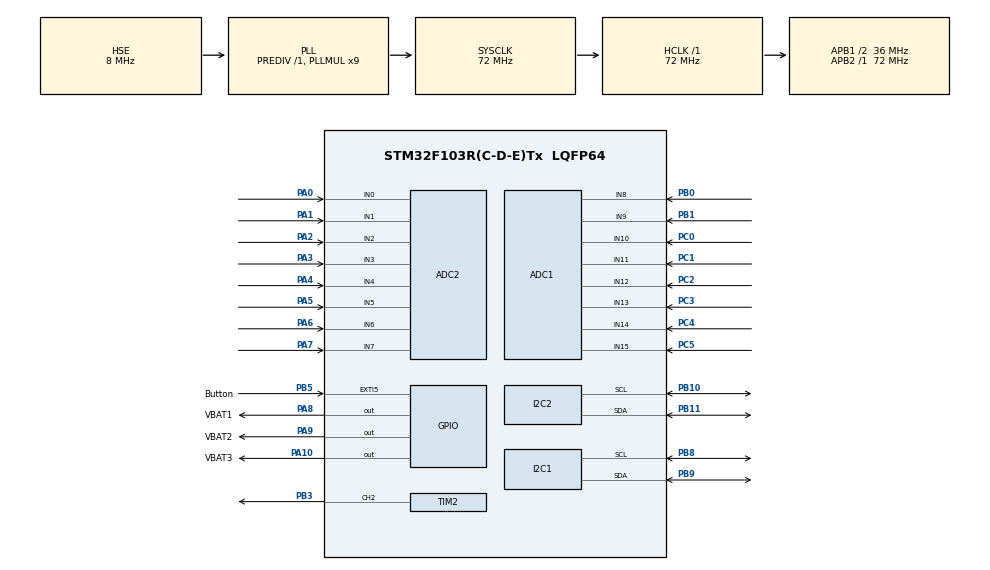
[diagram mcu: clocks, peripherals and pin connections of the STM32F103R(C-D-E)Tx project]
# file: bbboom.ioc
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ADC1.Channel-0\#ChannelRegularConversion=ADC_CHANNEL_8
ADC1.Channel-1\#ChannelRegularConversion=ADC_CHANNEL_9
ADC1.Channel-2\#ChannelRegularConversion=ADC_CHANNEL_10
ADC1.Channel-3\#ChannelRegularConversion=ADC_CHANNEL_11
ADC1.Channel-4\#ChannelRegularConversion=ADC_CHANNEL_12
ADC1.Channel-5\#ChannelRegularConversion=ADC_CHANNEL_13
ADC1.Channel-6\#ChannelRegularConversion=ADC_CHANNEL_14
ADC1.Channel-7\#ChannelRegularConversion=ADC_CHANNEL_15
ADC1.ContinuousConvMode=DISABLE
ADC1.DiscontinuousConvMode=ENABLE
ADC1.NbrOfConversion=8
ADC1.NbrOfConversionFlag=1
ADC1.Rank-0\#ChannelRegularConversion=1
ADC1.Rank-1\#ChannelRegularConversion=2
ADC1.Rank-2\#ChannelRegularConversion=3
ADC1.Rank-3\#ChannelRegularConversion=4
ADC1.Rank-4\#ChannelRegularConversion=5
ADC1.Rank-5\#ChannelRegularConversion=6
ADC1.Rank-6\#ChannelRegularConversion=7
ADC1.Rank-7\#ChannelRegularConversion=8
ADC1.SamplingTime-0\#ChannelRegularConversion=ADC_SAMPLETIME_28CYCLES_5
ADC1.SamplingTime-1\#ChannelRegularConversion=ADC_SAMPLETIME_28CYCLES_5
ADC1.SamplingTime-2\#ChannelRegularConversion=ADC_SAMPLETIME_41CYCLES_5
ADC1.SamplingTime-3\#ChannelRegularConversion=ADC_SAMPLETIME_28CYCLES_5
ADC1.SamplingTime-4\#ChannelRegularConversion=ADC_SAMPLETIME_28CYCLES_5
ADC1.SamplingTime-5\#ChannelRegularConversion=ADC_SAMPLETIME_28CYCLES_5
ADC1.SamplingTime-6\#ChannelRegularConversion=ADC_SAMPLETIME_28CYCLES_5
ADC1.SamplingTime-7\#ChannelRegularConversion=ADC_SAMPLETIME_28CYCLES_5
ADC1.master=1
ADC2.Channel-0\#ChannelRegularConversion=ADC_CHANNEL_0
ADC2.Channel-1\#ChannelRegularConversion=ADC_CHANNEL_1
ADC2.Channel-2\#ChannelRegularConversion=ADC_CHANNEL_2
ADC2.Channel-3\#ChannelRegularConversion=ADC_CHANNEL_3
ADC2.Channel-4\#ChannelRegularConversion=ADC_CHANNEL_4
ADC2.Channel-5\#ChannelRegularConversion=ADC_CHANNEL_5
ADC2.Channel-6\#ChannelRegularConversion=ADC_CHANNEL_6
ADC2.Channel-7\#ChannelRegularConversion=ADC_CHANNEL_7
ADC2.ContinuousConvMode=DISABLE
ADC2.DiscontinuousConvMode=ENABLE
ADC2.NbrOfConversion=8
ADC2.NbrOfConversionFlag=1
ADC2.Rank-0\#ChannelRegularConversion=1
ADC2.Rank-1\#ChannelRegularConversion=2
ADC2.Rank-2\#ChannelRegularConversion=3
ADC2.Rank-3\#ChannelRegularConversion=4
ADC2.Rank-4\#ChannelRegularConversion=5
ADC2.Rank-5\#ChannelRegularConversion=6
ADC2.Rank-6\#ChannelRegularConversion=7
ADC2.Rank-7\#ChannelRegularConversion=8
ADC2.SamplingTime-0\#ChannelRegularConversion=ADC_SAMPLETIME_28CYCLES_5
ADC2.SamplingTime-1\#ChannelRegularConversion=ADC_SAMPLETIME_28CYCLES_5
ADC2.SamplingTime-2\#ChannelRegularConversion=ADC_SAMPLETIME_28CYCLES_5
ADC2.SamplingTime-3\#ChannelRegularConversion=ADC_SAMPLETIME_28CYCLES_5
ADC2.SamplingTime-4\#ChannelRegularConversion=ADC_SAMPLETIME_28CYCLES_5
ADC2.SamplingTime-5\#ChannelRegularConversion=ADC_SAMPLETIME_28CYCLES_5
ADC2.SamplingTime-6\#ChannelRegularConversion=ADC_SAMPLETIME_28CYCLES_5
ADC2.SamplingTime-7\#ChannelRegularConversion=ADC_SAMPLETIME_28CYCLES_5
Mcu.Family=STM32F1
Mcu.Name=STM32F103R(C-D-E)Tx
Mcu.Package=LQFP64
NVIC.EXTI9_5_IRQn=true\:0\:0\:false\:false\:true\:true\:true\:true
NVIC.I2C1_ER_IRQn=true\:0\:0\:false\:false\:true\:true\:true\:true
NVIC.I2C2_ER_IRQn=true\:0\:0\:false\:false\:true\:true\:true\:true
NVIC.I2C2_EV_IRQn=true\:0\:0\:false\:false\:true\:true\:true\:true
NVIC.PriorityGroup=NVIC_PRIORITYGROUP_4
NVIC.TIM1_UP_IRQn=true\:1\:0\:true\:false\:true\:true\:true\:true
PA0-WKUP.Signal=ADCx_IN0
PA1.Signal=ADCx_IN1
PA10.GPIO_Label=VBAT3
PA10.GPIO_ModeDefaultOutputPP=GPIO_MODE_OUTPUT_PP
PA10.GPIO_PuPd=GPIO_PULLDOWN
PA10.GPIO_Speed=GPIO_SPEED_FREQ_MEDIUM
PA10.Signal=GPIO_Output
PA13.Mode=Serial_Wire
PA13.Signal=SYS_JTMS-SWDIO
PA14.Mode=Serial_Wire
PA14.Signal=SYS_JTCK-SWCLK
PA2.Signal=ADCx_IN2
PA3.Signal=ADCx_IN3
PA4.Signal=ADCx_IN4
PA5.Signal=ADCx_IN5
PA6.Signal=ADCx_IN6
PA7.Signal=ADCx_IN7
PA8.GPIO_Label=VBAT1
PA8.GPIO_ModeDefaultOutputPP=GPIO_MODE_OUTPUT_PP
PA8.GPIO_PuPd=GPIO_PULLDOWN
PA8.GPIO_Speed=GPIO_SPEED_FREQ_MEDIUM
PA8.Signal=GPIO_Output
PA9.GPIO_Label=VBAT2
PA9.GPIO_ModeDefaultOutputPP=GPIO_MODE_OUTPUT_PP
PA9.GPIO_PuPd=GPIO_PULLDOWN
PA9.GPIO_Speed=GPIO_SPEED_FREQ_MEDIUM
PA9.PinState=GPIO_PIN_RESET
PA9.Signal=GPIO_Output
PB0.Signal=ADCx_IN8
PB1.Signal=ADCx_IN9
PB10.Mode=I2C
PB10.Signal=I2C2_SCL
PB11.Mode=I2C
PB11.Signal=I2C2_SDA
PB3.Signal=S_TIM2_CH2
PB5.GPIO_Label=Button
PB5.GPIO_ModeDefaultEXTI=GPIO_MODE_IT_FALLING
PB5.GPIO_PuPd=GPIO_NOPULL
PB5.Signal=GPXTI5
PB8.Mode=I2C
PB8.Signal=I2C1_SCL
PB9.Mode=I2C
PB9.Signal=I2C1_SDA
PC0.Signal=ADCx_IN10
PC1.Signal=ADCx_IN11
PC14-OSC32_IN.Mode=LSE-External-Oscillator
PC14-OSC32_IN.Signal=RCC_OSC32_IN
PC15-OSC32_OUT.Mode=LSE-External-Oscillator
PC15-OSC32_OUT.Signal=RCC_OSC32_OUT
PC2.Signal=ADCx_IN12
PC3.Signal=ADCx_IN13
PC4.Signal=ADCx_IN14
PC5.Signal=ADCx_IN15
PD0-OSC_IN.Mode=HSE-External-Oscillator
PD0-OSC_IN.Signal=RCC_OSC_IN
PD1-OSC_OUT.Mode=HSE-External-Oscillator
PD1-OSC_OUT.Signal=RCC_OSC_OUT
ProjectManager.HeapSize=0x200
ProjectManager.StackSize=0x400
ProjectManager.TargetToolchain=Makefile
RCC.ADCPresc=RCC_ADCPCLK2_DIV6
RCC.AHBFreq_Value=72000000
RCC.APB1CLKDivider=RCC_HCLK_DIV2
RCC.APB1Freq_Value=36000000
RCC.APB1TimFreq_Value=72000000
RCC.APB2Freq_Value=72000000
RCC.APB2TimFreq_Value=72000000
RCC.HCLKFreq_Value=72000000
RCC.PLLMUL=RCC_PLL_MUL9
RCC.PLLSourceVirtual=RCC_PLLSOURCE_HSE
RCC.SYSCLKFreq_VALUE=72000000
RCC.SYSCLKSource=RCC_SYSCLKSOURCE_PLLCLK
RCC.USBFreq_Value=72000000
SH.ADCx_IN0.0=ADC2_IN0,IN0
SH.ADCx_IN1.0=ADC2_IN1,IN1
SH.ADCx_IN10.0=ADC1_IN10,IN10
SH.ADCx_IN11.0=ADC1_IN11,IN11
SH.ADCx_IN12.0=ADC1_IN12,IN12
SH.ADCx_IN13.0=ADC1_IN13,IN13
SH.ADCx_IN14.0=ADC1_IN14,IN14
SH.ADCx_IN15.0=ADC1_IN15,IN15
SH.ADCx_IN2.0=ADC2_IN2,IN2
SH.ADCx_IN3.0=ADC2_IN3,IN3
SH.ADCx_IN4.0=ADC2_IN4,IN4
SH.ADCx_IN5.0=ADC2_IN5,IN5
SH.ADCx_IN6.0=ADC2_IN6,IN6
SH.ADCx_IN7.0=ADC2_IN7,IN7
SH.ADCx_IN8.0=ADC1_IN8,IN8
SH.ADCx_IN9.0=ADC1_IN9,IN9
SH.S_TIM2_CH2.0=TIM2_CH2,PWM Generation2 CH2
TIM1.AutoReloadPreload=TIM_AUTORELOAD_PRELOAD_ENABLE
TIM1.Period=9999
TIM1.Prescaler=7199
TIM2.AutoReloadPreload=TIM_AUTORELOAD_PRELOAD_ENABLE
TIM2.Channel-PWM\ Generation2\ CH2=TIM_CHANNEL_2
TIM2.Period=9999
TIM2.Prescaler=7199
VP_TIM1_VS_ClockSourceINT.Mode=Internal
VP_TIM2_VS_ClockSourceINT.Mode=Internal
board=custom

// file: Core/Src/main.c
/* USER CODE BEGIN Header */
/**
  ******************************************************************************
  * @file           : main.c
  * @brief          : Main program body
  ******************************************************************************
  * @attention
  *
  * Copyright (c) 2024 STMicroelectronics.
  * All rights reserved.
  *
  * This software is licensed under terms that can be found in the LICENSE file
  * in the root directory of this software component.
  * If no LICENSE file comes with this software, it is provided AS-IS.
  *
  ******************************************************************************
  */
/* USER CODE END Header */
#include "main.h"
#include "adc.h"
#include "i2c.h"
#include "tim.h"
#include "gpio.h"

/* USER CODE BEGIN Includes */
#include "oled.h"
#include "ADS1015.h"
#include "Battery.h"
#include "UI.h"
#include "FSM.h"
/* USER CODE END Includes */

void SystemClock_Config(void);

/* USER CODE BEGIN 0 */
int i2c_state=0;
/* USER CODE END 0 */

int main(void)
{

  /* MCU Configuration--------------------------------------------------------*/

  /* Reset of all peripherals, Initializes the Flash interface and the Systick. */
  HAL_Init();

  /* Configure the system clock */
  SystemClock_Config();

  /* Initialize all configured peripherals */
  MX_GPIO_Init();
  MX_ADC1_Init();
  MX_ADC2_Init();
  MX_I2C1_Init();
  MX_I2C2_Init();
  MX_TIM1_Init();
  MX_TIM2_Init();
  /* USER CODE BEGIN 2 */
  OLED_Init();
  UI_ShowRUAGH();
  HAL_Delay(1000);
  Battery_Init(Battery,3.8,3.7);
  FSM_StateRefresh(Battery,&BB_fsm);
  // ADS1015_Init();
  // ADS1015_Config(hi2c2,ADS1015_SINGLE_END,0);
  // ADS1015_Config_Register(hi2c2,ADS1015_REG_POINTER_CONFIG,ADS1015_CONFIG);

  // ADS1015_Config(hi2c2,ADS1015_SINGLE_END,2);
  // ADS1015_Config_Register(hi2c2,ADS1015_REG_POINTER_CONFIG,ADS1015_CONFIG);

  // i2c_state=AD1015_Check(hi2c2);
  // i2c_state=HAL_I2C_IsDeviceReady(&hi2c2, ADS1015_ADDRESS<<1, 2, 1000);
  // Battery_Init(Battery,3.8,3.7);
  // Show_Normal_UI(Battery,1,1,1,1);

  HAL_TIM_Base_Start_IT(&htim1); //定时�?1使能

  // 使能timx的�?�靓y
  HAL_TIM_PWM_Start(&htim2,TIM_CHANNEL_2);

  /* USER CODE END 2 */

  /* Infinite loop */
  /* USER CODE BEGIN WHILE */
  while (1)
  {
    // i2c_state++;
    /* USER CODE END WHILE */

  }
}

void SystemClock_Config(void)
{
  RCC_OscInitTypeDef RCC_OscInitStruct = {0};
  RCC_ClkInitTypeDef RCC_ClkInitStruct = {0};
  RCC_PeriphCLKInitTypeDef PeriphClkInit = {0};

  /** Initializes the RCC Oscillators according to the specified parameters
  * in the RCC_OscInitTypeDef structure.
  */
  RCC_OscInitStruct.OscillatorType = RCC_OSCILLATORTYPE_HSE;
  RCC_OscInitStruct.HSEState = RCC_HSE_ON;
  RCC_OscInitStruct.HSEPredivValue = RCC_HSE_PREDIV_DIV1;
  RCC_OscInitStruct.HSIState = RCC_HSI_ON;
  RCC_OscInitStruct.PLL.PLLState = RCC_PLL_ON;
  RCC_OscInitStruct.PLL.PLLSource = RCC_PLLSOURCE_HSE;
  RCC_OscInitStruct.PLL.PLLMUL = RCC_PLL_MUL9;
  if (HAL_RCC_OscConfig(&RCC_OscInitStruct) != HAL_OK)
  {
    Error_Handler();
  }

  /** Initializes the CPU, AHB and APB buses clocks
  */
  RCC_ClkInitStruct.ClockType = RCC_CLOCKTYPE_HCLK|RCC_CLOCKTYPE_SYSCLK
                              |RCC_CLOCKTYPE_PCLK1|RCC_CLOCKTYPE_PCLK2;
  RCC_ClkInitStruct.SYSCLKSource = RCC_SYSCLKSOURCE_PLLCLK;
  RCC_ClkInitStruct.AHBCLKDivider = RCC_SYSCLK_DIV1;
  RCC_ClkInitStruct.APB1CLKDivider = RCC_HCLK_DIV2;
  RCC_ClkInitStruct.APB2CLKDivider = RCC_HCLK_DIV1;

  if (HAL_RCC_ClockConfig(&RCC_ClkInitStruct, FLASH_LATENCY_2) != HAL_OK)
  {
    Error_Handler();
  }
  PeriphClkInit.PeriphClockSelection = RCC_PERIPHCLK_ADC;
  PeriphClkInit.AdcClockSelection = RCC_ADCPCLK2_DIV6;
  if (HAL_RCCEx_PeriphCLKConfig(&PeriphClkInit) != HAL_OK)
  {
    Error_Handler();
  }
}

void Error_Handler(void)
{
  __disable_irq();
  while (1)
  {
  }
}
